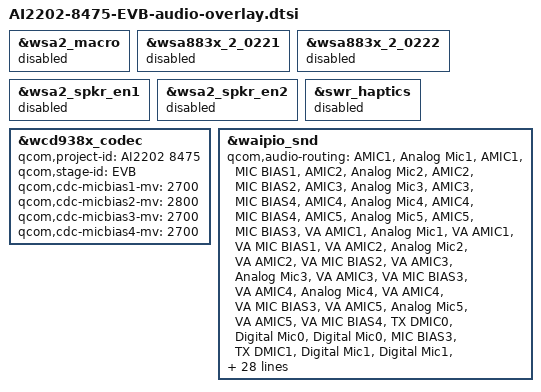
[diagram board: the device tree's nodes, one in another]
#include "waipio-audio-overlay.dtsi"

&wsa2_macro {
	status = "disabled";
};

&wsa883x_2_0221 {
	status = "disabled";
};

&wsa883x_2_0222 {
	status = "disabled";
};

&wsa2_spkr_en1 {
	status = "disabled";
};

&wsa2_spkr_en2 {
	status = "disabled";
};

&swr_haptics {
	status = "disabled";
};

&wcd938x_codec {
	qcom,project-id = "AI2202 8475";
	qcom,stage-id = "EVB";
	qcom,cdc-micbias1-mv = <2700>;
	qcom,cdc-micbias2-mv = <2800>;
	qcom,cdc-micbias3-mv = <2700>;
	qcom,cdc-micbias4-mv = <2700>;
};

&waipio_snd {
	qcom,audio-routing =
		"AMIC1", "Analog Mic1",
		"AMIC1", "MIC BIAS1",
		"AMIC2", "Analog Mic2",
		"AMIC2", "MIC BIAS2",
		"AMIC3", "Analog Mic3",
		"AMIC3", "MIC BIAS4",
		"AMIC4", "Analog Mic4",
		"AMIC4", "MIC BIAS4",
		"AMIC5", "Analog Mic5",
		"AMIC5", "MIC BIAS3",
		"VA AMIC1", "Analog Mic1",
		"VA AMIC1", "VA MIC BIAS1",
		"VA AMIC2", "Analog Mic2",
		"VA AMIC2", "VA MIC BIAS2",
		"VA AMIC3", "Analog Mic3",
		"VA AMIC3", "VA MIC BIAS3",
		"VA AMIC4", "Analog Mic4",
		"VA AMIC4", "VA MIC BIAS3",
		"VA AMIC5", "Analog Mic5",
		"VA AMIC5", "VA MIC BIAS4",
		"TX DMIC0", "Digital Mic0",
		"Digital Mic0", "MIC BIAS3",
		"TX DMIC1", "Digital Mic1",
		"Digital Mic1", "MIC BIAS3",
		"TX DMIC2", "Digital Mic2",
		"Digital Mic2", "MIC BIAS1",
		"TX DMIC3", "Digital Mic3",
		"Digital Mic3", "MIC BIAS1",
		"IN1_HPHL", "HPHL_OUT",
		"IN2_HPHR", "HPHR_OUT",
		"IN3_AUX", "AUX_OUT",
		"WSA SRC0_INP", "SRC0",
		"WSA_TX DEC0_INP", "TX DEC0 MUX",
		"WSA_TX DEC1_INP", "TX DEC1 MUX",
		"RX_TX DEC0_INP", "TX DEC0 MUX",
		"RX_TX DEC1_INP", "TX DEC1 MUX",
		"RX_TX DEC2_INP", "TX DEC2 MUX",
		"RX_TX DEC3_INP", "TX DEC3 MUX",
		"SpkrLeft IN", "WSA_SPK1 OUT",
		"SpkrRight IN", "WSA_SPK2 OUT",
		"TX SWR_INPUT", "WCD_TX_OUTPUT",
		"VA SWR_INPUT", "VA_SWR_CLK",
		"VA SWR_INPUT", "WCD_TX_OUTPUT",
		"VA_AIF1 CAP", "VA_SWR_CLK",
		"VA_AIF2 CAP", "VA_SWR_CLK",
		"VA_AIF3 CAP", "VA_SWR_CLK",
		"VA DMIC0", "Digital Mic0",
		"VA DMIC1", "Digital Mic1",
		"VA DMIC2", "Digital Mic2",
		"VA DMIC3", "Digital Mic3",
		"Digital Mic0", "VA MIC BIAS3",
		"Digital Mic1", "VA MIC BIAS3",
		"Digital Mic2", "VA MIC BIAS1",
		"Digital Mic3", "VA MIC BIAS1";

	qcom,cdc-dmic01-gpios;
	qcom,cdc-dmic23-gpios;
	qcom,cdc-dmic45-gpios;
	asoc-codec  = <&stub_codec>, <&lpass_cdc>,
			<&wcd938x_codec>, <&wsa883x_0221>, <&wsa883x_0222>;
	asoc-codec-names = "msm-stub-codec.1", "lpass-cdc",
			"wcd938x_codec",
			 "wsa-codec1", "wsa-codec2";
};
